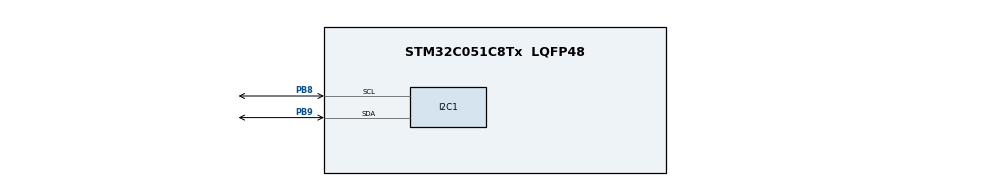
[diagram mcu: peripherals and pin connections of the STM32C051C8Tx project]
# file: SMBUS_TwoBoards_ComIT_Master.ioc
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I2C1.I2C_Fall_Time=0
I2C1.I2C_Rise_Time=0
I2C1.SMBusDualAddressMode=SMBUS_DUALADDRESS_ENABLE
I2C1.SMBusOwnAddress=0x42
I2C1.SMBusOwnAddress2=0xFF
I2C1.SMBusPacketErrorCheckMode=SMBUS_PEC_ENABLE
I2C1.SMBusPeripheralMode=SMBUS_PERIPHERAL_MODE_SMBUS_HOST
I2C1.Timeout=0x00008249
I2C1.Timing=0x20303E5D
Mcu.Family=STM32C0
Mcu.Name=STM32C051C8Tx
Mcu.Package=LQFP48
NVIC.I2C1_IRQn=true\:0\:0\:false\:false\:true\:true\:true\:true
PB8.GPIO_Pu=GPIO_PULLUP
PB8.GPIO_Speed=GPIO_SPEED_FREQ_VERY_HIGH
PB8.Mode=SMBus-two-wire-Interface
PB8.Signal=I2C1_SCL
PB9.GPIO_Pu=GPIO_PULLUP
PB9.GPIO_Speed=GPIO_SPEED_FREQ_VERY_HIGH
PB9.Mode=SMBus-two-wire-Interface
PB9.Signal=I2C1_SDA
ProjectManager.HeapSize=0x200
ProjectManager.StackSize=0x400
ProjectManager.TargetToolchain=EWARM V9.20
RCC.ADCFreq_Value=48000000
RCC.AHBFreq_Value=48000000
RCC.CortexFreq_Value=48000000
RCC.EXTERNAL_CLOCK_VALUE=12288000
RCC.HCLKFreq_Value=48000000
RCC.HSE_VALUE=8000000
RCC.HSISYSCLKDivider=RCC_HSI_DIV1
RCC.HSI_VALUE=48000000
RCC.LSE_VALUE=32768
RCC.SYSCLKFreq_VALUE=48000000
board=custom

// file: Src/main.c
/* USER CODE BEGIN Header */
/**
  ******************************************************************************
  * @file    SMBUS/SMBUS_TwoBoards_ComIT_Master/Src/main.c
  * @author  MCD Application Team
  * @brief   This sample code shows how to use STM32C0xx SMBUS HAL API to
  *          manage a Communication between a Master and a Slave based
  *          on Interrupt procedure.
  ******************************************************************************
  * @attention
  *
  * Copyright (c) 2024 STMicroelectronics.
  * All rights reserved.
  *
  * This software is licensed under terms that can be found in the LICENSE file
  * in the root directory of this software component.
  * If no LICENSE file comes with this software, it is provided AS-IS.
  *
  ******************************************************************************
  */
/* USER CODE END Header */
#include "main.h"

/* USER CODE BEGIN PD */
#define SMBUS_ADDRESS          0x42
#define SMBUS_PEC_SIZE         0x1

/* Address match */
__IO uint32_t SlaveAddrMatchCode = 0;

/* Buffer used for transmission */
uint8_t aTxBuffer[] = " ****SMBUS_TwoBoards communication using Interrupts****  ****SMBUS_TwoBoards communication using Interrupts****  ****SMBUS_TwoBoards communication using Interrupts**** ";

/* Buffer used for data and PEC reception */
uint8_t aRxBuffer[RXBUFFERSIZE + SMBUS_PEC_SIZE];
/* USER CODE END PD */

SMBUS_HandleTypeDef hsmbus1;

void SystemClock_Config(void);
static void MX_GPIO_Init(void);
static void MX_I2C1_SMBUS_Init(void);
/* USER CODE BEGIN PFP */
static uint16_t Buffercmp(uint8_t* pBuffer1, uint8_t* pBuffer2, uint16_t BufferLength);
static void WaitOnPushButton(void);
/* USER CODE END PFP */

int main(void)
{

  /* MCU Configuration--------------------------------------------------------*/

  /* Reset of all peripherals, Initializes the Flash interface and the Systick. */
  HAL_Init();

  /* Configure the system clock */
  SystemClock_Config();

  /* USER CODE BEGIN SysInit */
  /* Configure LED4 */
  BSP_LED_Init(LED4);
  /* USER CODE END SysInit */

  /* Initialize all configured peripherals */
  MX_GPIO_Init();
  MX_I2C1_SMBUS_Init();
  /* USER CODE BEGIN 2 */

  /* Configure User push-button */
  BSP_PB_Init(BUTTON_USER, BUTTON_MODE_GPIO);

  /* Wait for USER push-button press before starting the Communication */
  WaitOnPushButton();

  /* The board sends the message and expects to receive it back */

  /*##-2- Start the transmission process #####################################*/
  /* While the SMBUS in reception process, user can transmit data through
  "aTxBuffer" buffer */
  do
  {
    if (HAL_SMBUS_Master_Transmit_IT(&hsmbus1, (uint16_t)SMBUS_ADDRESS, (uint8_t*)aTxBuffer, TXBUFFERSIZE + SMBUS_PEC_SIZE, SMBUS_FIRST_AND_LAST_FRAME_WITH_PEC) != HAL_OK)
    {
      Error_Handler();
    }

    while (HAL_SMBUS_GetState(&hsmbus1) != HAL_SMBUS_STATE_READY)
    {
    }

    /* Error_Handler() function is called when Timeout error occurs.
    When Acknowledge failure occurs (Slave don't acknowledge its address)
    Master restarts communication */
  }
  while (HAL_SMBUS_GetError(&hsmbus1) == HAL_SMBUS_ERROR_ACKF);

  /* Turn LED4 on: Transfer in Transmission process is correct */
  BSP_LED_On(LED4);

  /* Wait for USER push-button press before starting the Communication */
  WaitOnPushButton();

  /*##-3- Put SMBUS peripheral in reception process ############################*/
  do
  {
    if (HAL_SMBUS_Master_Receive_IT(&hsmbus1, (uint16_t)SMBUS_ADDRESS, (uint8_t *)aRxBuffer, RXBUFFERSIZE + SMBUS_PEC_SIZE, SMBUS_FIRST_AND_LAST_FRAME_WITH_PEC) != HAL_OK)
    {
      Error_Handler();
    }

    while (HAL_SMBUS_GetState(&hsmbus1) != HAL_SMBUS_STATE_READY)
    {
    }

    /* Error_Handler() function is called when Timeout error occurs.
    When Acknowledge failure occurs (Slave don't acknowledge it's address)
    Master restarts communication */
  }
  while (HAL_SMBUS_GetError(&hsmbus1) == HAL_SMBUS_ERROR_ACKF);

  /* Compare PEC register and sent PEC #######################################*/
  if (aRxBuffer[RXBUFFERSIZE + SMBUS_PEC_SIZE - 1] != hsmbus1.Instance->PECR)
  {
    /* Processing Error */
    Error_Handler();
  }

  /* Turn LED4 off: Transfer in reception process is correct */
  BSP_LED_Off(LED4);

  /*##-4- Compare the sent and received buffers ##############################*/
  if (Buffercmp((uint8_t*)aTxBuffer, (uint8_t*)aRxBuffer, RXBUFFERSIZE))
  {
    /* Processing Error */
    Error_Handler();
  }

  /* USER CODE END 2 */

  /* Infinite loop */
  while (1)
  {

  }
}

void SystemClock_Config(void)
{
  RCC_OscInitTypeDef RCC_OscInitStruct = {0};
  RCC_ClkInitTypeDef RCC_ClkInitStruct = {0};

  __HAL_FLASH_SET_LATENCY(FLASH_LATENCY_1);

  /** Initializes the RCC Oscillators according to the specified parameters
  * in the RCC_OscInitTypeDef structure.
  */
  RCC_OscInitStruct.OscillatorType = RCC_OSCILLATORTYPE_HSI;
  RCC_OscInitStruct.HSIState = RCC_HSI_ON;
  RCC_OscInitStruct.HSIDiv = RCC_HSI_DIV1;
  RCC_OscInitStruct.HSICalibrationValue = RCC_HSICALIBRATION_DEFAULT;
  if (HAL_RCC_OscConfig(&RCC_OscInitStruct) != HAL_OK)
  {
    Error_Handler();
  }

  /** Initializes the CPU, AHB and APB buses clocks
  */
  RCC_ClkInitStruct.ClockType = RCC_CLOCKTYPE_HCLK|RCC_CLOCKTYPE_SYSCLK
                              |RCC_CLOCKTYPE_PCLK1;
  RCC_ClkInitStruct.SYSCLKSource = RCC_SYSCLKSOURCE_HSI;
  RCC_ClkInitStruct.SYSCLKDivider = RCC_SYSCLK_DIV1;
  RCC_ClkInitStruct.AHBCLKDivider = RCC_HCLK_DIV1;
  RCC_ClkInitStruct.APB1CLKDivider = RCC_APB1_DIV1;

  if (HAL_RCC_ClockConfig(&RCC_ClkInitStruct, FLASH_LATENCY_1) != HAL_OK)
  {
    Error_Handler();
  }
}

static void MX_I2C1_SMBUS_Init(void)
{

  hsmbus1.Instance = I2C1;
  hsmbus1.Init.Timing = 0x20303E5D;
  hsmbus1.Init.AnalogFilter = SMBUS_ANALOGFILTER_ENABLE;
  hsmbus1.Init.OwnAddress1 = 0x42;
  hsmbus1.Init.AddressingMode = SMBUS_ADDRESSINGMODE_7BIT;
  hsmbus1.Init.DualAddressMode = SMBUS_DUALADDRESS_ENABLE;
  hsmbus1.Init.OwnAddress2 = 0xFF;
  hsmbus1.Init.OwnAddress2Masks = SMBUS_OA2_NOMASK;
  hsmbus1.Init.GeneralCallMode = SMBUS_GENERALCALL_DISABLE;
  hsmbus1.Init.NoStretchMode = SMBUS_NOSTRETCH_DISABLE;
  hsmbus1.Init.PacketErrorCheckMode = SMBUS_PEC_ENABLE;
  hsmbus1.Init.PeripheralMode = SMBUS_PERIPHERAL_MODE_SMBUS_HOST;
  hsmbus1.Init.SMBusTimeout = 0x00008249;
  if (HAL_SMBUS_Init(&hsmbus1) != HAL_OK)
  {
    Error_Handler();
  }

  /** Configure Digital filter
  */
  if (HAL_SMBUS_ConfigDigitalFilter(&hsmbus1, 0) != HAL_OK)
  {
    Error_Handler();
  }

}

static void MX_GPIO_Init(void)
{

  /* GPIO Ports Clock Enable */
  __HAL_RCC_GPIOB_CLK_ENABLE();

}

/* USER CODE BEGIN 4 */
/**
  * @brief  SMBUS error callback.
  * @param  SMBUSHandle: SMBUS handle
  * @note   This example shows a simple way to report transfer error, and you can
  *         add your own implementation.
  * @retval None
  */
void HAL_SMBUS_ErrorCallback(SMBUS_HandleTypeDef *SMBUSHandle)
{
  /** Error_Handler() function is called when error occurs.
  * 1- When Slave doesn't acknowledge its address, Master restarts communication.
  * 2- When Master doesn't acknowledge the last data transferred, Slave doesn't care in this example.
  */
  if (HAL_SMBUS_GetError(SMBUSHandle) != HAL_SMBUS_ERROR_ACKF)
  {
    /* LED4 toggle */
    BSP_LED_Toggle(LED4);
    HAL_Delay(1000);
  }
}

/**
  * @brief  Compares two buffers.
  * @param  pBuffer1, pBuffer2: buffers to be compared.
  * @param  BufferLength: buffer's length
  * @retval 0  : pBuffer1 identical to pBuffer2
  *         >0 : pBuffer1 differs from pBuffer2
  */
static uint16_t Buffercmp(uint8_t* pBuffer1, uint8_t* pBuffer2, uint16_t BufferLength)
{
  while (BufferLength--)
  {
    if ((*pBuffer1) != *pBuffer2)
    {
      return BufferLength;
    }
    pBuffer1++;
    pBuffer2++;
  }

  return 0;
}

/**
  * @brief  Wait for user to press user button.
  * @param  None
  * @retval None
  */
static void WaitOnPushButton(void)
{
  /* Wait for User push-button press before starting the Communication */
  while (BSP_PB_GetState(BUTTON_USER) != GPIO_PIN_RESET)
  {
    BSP_LED_Toggle(LED4);
    HAL_Delay(100);
  }

  BSP_LED_Off(LED4);

  /* Delay to avoid that possible signal rebound is taken as button release */
  HAL_Delay(50);

  /* Wait for User push-button release before starting the Communication */
  while (BSP_PB_GetState(BUTTON_USER) != GPIO_PIN_SET)
  {
  }
}
/* USER CODE END 4 */

void Error_Handler(void)
{
  /* USER CODE BEGIN Error_Handler_Debug */
  __disable_irq();

  while (1)
  {
    /* LED4 toggle */
    BSP_LED_Toggle(LED4);
    HAL_Delay(1000);
  }
  /* USER CODE END Error_Handler_Debug */
}
